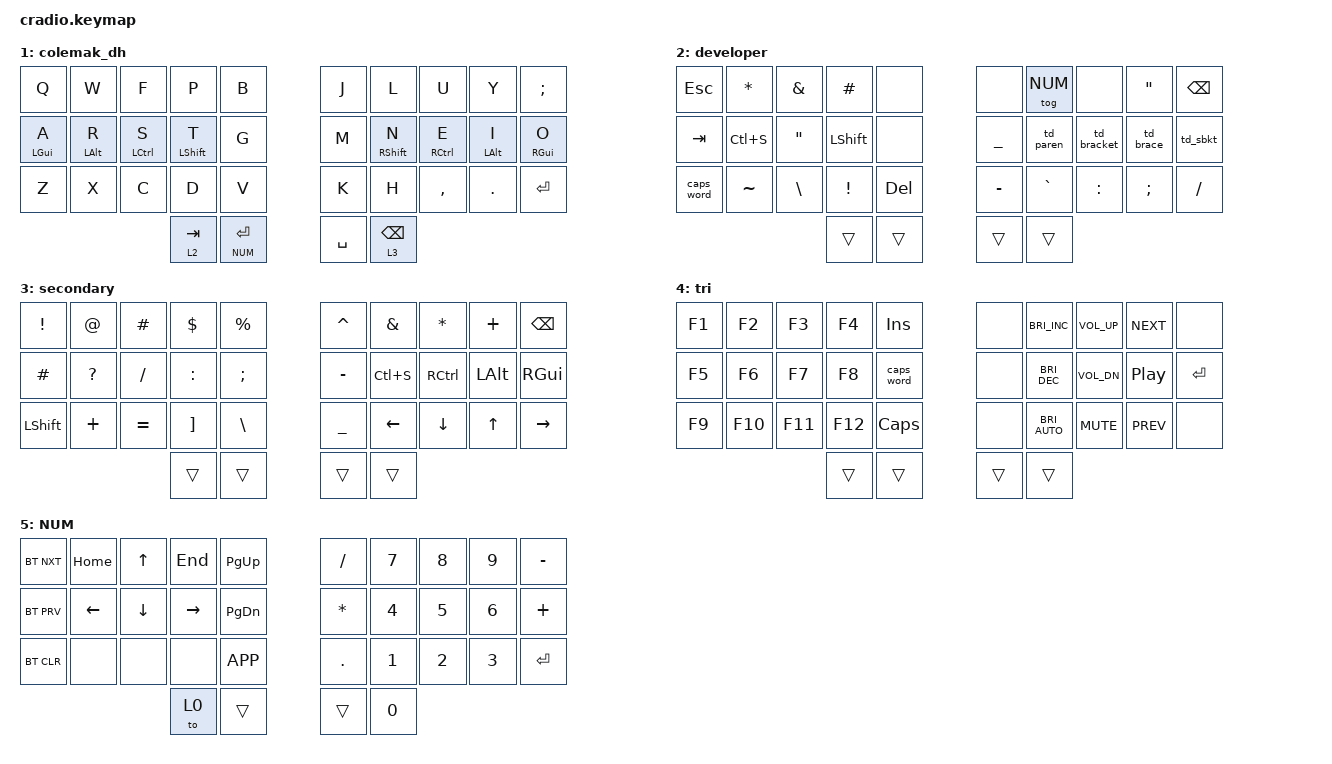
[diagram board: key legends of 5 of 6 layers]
/*
 * Copyright (c) 2020 The ZMK Contributors
 *
 * SPDX-License-Identifier: MIT
 */

#include <behaviors.dtsi>
#include <dt-bindings/zmk/keys.h>
#include <dt-bindings/zmk/bt.h>

#define QWERTY  0
#define COLEMAK 1
#define EDITOR  2
#define SECOND  3
#define TRI     4
#define NUM     5

// Home row mods macros
#define HRML(k1,k2,k3,k4) &ht LGUI k1  &ht LALT k2  &ht LCTRL k3  &ht LSHFT k4
#define HRMR(k1,k2,k3,k4) &ht RSHFT k1  &ht RCTRL k2  &ht LALT k3  &ht RGUI k4

&mt {
    tapping-term-ms = <500>;
};

/ {
    behaviors {
        td_paren: tap_dance_parenthesis {
            compatible = "zmk,behavior-tap-dance";
            label = "TAP_DANCE_PARENTHESIS";
            #binding-cells = <0>;
            tapping-term-ms = <200>;
            bindings = <&kp LEFT_PARENTHESIS>, <&kp RIGHT_PARENTHESIS>;
        };

        td_bracket: tap_dance_bracket {
            compatible = "zmk,behavior-tap-dance";
            label = "TAP_DANCE_BRACKET";
            #binding-cells = <0>;
            tapping-term-ms = <200>;
            bindings = <&kp LEFT_BRACKET>, <&kp RIGHT_BRACKET>;
        };

        td_brace: tap_dance_brace {
            compatible = "zmk,behavior-tap-dance";
            label = "TAP_DANCE_BRACE";
            #binding-cells = <0>;
            tapping-term-ms = <200>;
            bindings = <&kp LEFT_BRACE>, <&kp RIGHT_BRACE>;
        };

        td_sbkt: tap_dance_square_bracket {
            compatible = "zmk,behavior-tap-dance";
            label = "TAP_DANCE_SQUARE_BRACKET";
            #binding-cells = <0>;
            tapping-term-ms = <200>;
            bindings = <&kp LESS_THAN>, <&kp GREATER_THAN>;
        };

        hm: homerow_mods {
            compatible = "zmk,behavior-hold-tap";
            label = "HOMEROW_MODS";
            #binding-cells = <2>;
            flavor = "tap-preferred";
            tapping-term-ms = <200>;
            quick-tap-ms = <125>;
            global-quick-tap;
            bindings = <&kp>, <&kp>;
        };

        ht: hold_tap {
            label = "hold_tap";
            compatible = "zmk,behavior-hold-tap";
            #binding-cells = <2>;
            flavor = "tap-preferred";
            tapping-term-ms = <220>;
            quick-tap-ms = <150>;
            global-quick-tap;
            bindings = <&kp>, <&kp>;
        };
    };

    combos {
        compatible = "zmk,combos";
        
        combo_esc {
            timeout-ms = <50>;
            key-positions = <0 1>;
            bindings = <&kp ESC>;
        };
        
        combo_tab {
            timeout-ms = <50>;
            key-positions = <10 11>;
            bindings = <&kp TAB>;
        };
        
        combo_backspace {
            timeout-ms = <50>;
            key-positions = <8 9>;
            bindings = <&kp BACKSPACE>;
        };
        
        combo_qwerty {
            timeout-ms = <50>;
            key-positions = <30 33>;
            layers = <COLEMAK>;
            bindings = <&to QWERTY>;
        };
        
        combo_colemak {
            timeout-ms = <50>;
            key-positions = <30 33>;
            layers = <QWERTY>;
            bindings = <&to COLEMAK>;
        };
        
        layer_reset {
            timeout-ms = <50>;
            key-positions = <0 4 5 9>;
            bindings = <&to COLEMAK>;
        };
    };

    conditional_layers {
        compatible = "zmk,conditional-layers";
        tri_layer {
            if-layers = <EDITOR SECOND>;
            then-layer = <TRI>;
        };
    };

    keymap {
        // TODO: homerow mods on additional layers
        // TODO: mod to access control layer
        // TODO: windows, linux, iPadOs shortcut layers (enable layers and then use conditional layers for shortcut directing)
        // TODO: move SEMICOLON off of colemak/qwerty layers? maybe replace with ampersand?
        // TODO: modifiers to access F-keys and top-row symbols from numpad

        compatible = "zmk,keymap";
                
        qwerty {
            bindings = <
        //╭──────────┬──────────┬──────────┬──────────┬──────────╮   ╭──────────┬──────────┬──────────┬──────────┬──────────╮
        //│  Q       │  W       │  E       │  R       │  T       │   │  Y       │  U       │  I       │  O       │  P       │
            &kp Q      &kp W      &kp E      &kp R      &kp T          &kp Y      &kp U      &kp I      &kp O      &kp P
        //├──────────┼──────────┼──────────┼──────────┼──────────┤   ├──────────┼──────────┼──────────┼──────────┼──────────┤
        //│  A       │  S       │  D       │  F       │  G       │   │  H       │  J       │  K       │  L       │ ' "      │
            HRML(A,        S,         D,         F)     &kp G          &kp H      HRMR(J,        K,         L,        SQT)
        //├──────────┼──────────┼──────────┼──────────┼──────────┤   ├──────────┼──────────┼──────────┼──────────┼──────────┤
        //│  Z       │  X       │  C       │  V       │  B       │   │  N       │  M       │ , <      │ . >      │ / ?      │
            &kp Z      &kp X      &kp C      &kp V      &kp B          &kp N      &kp M      &kp COMMA  &kp DOT    &kp FSLH
        //╰──────────┴──────────┴──────────┼──────────┼──────────┤   ├──────────┼──────────┼──────────┴──────────┴──────────╯
                                            &lt 2 TAB  &lt 5 ENTER    &kp SPACE  &lt 3 BSPC
        //                                 ╰──────────┴──────────╯   ╰──────────┴──────────╯
            >;
        };
                
        colemak_dh {
            bindings = <
        //╭──────────┬──────────┬──────────┬──────────┬──────────╮   ╭──────────┬──────────┬──────────┬──────────┬──────────╮
        //│  Q       │  W       │  F       │  P       │  B       │   │  J       │  L       │  U       │  Y       │  ; :     │
           &kp Q      &kp W      &kp F      &kp P      &kp B          &kp J      &kp L      &kp U      &kp Y      &kp SEMICOLON
        //├──────────┼──────────┼──────────┼──────────┼──────────┤   ├──────────┼──────────┼──────────┼──────────┼──────────┤
        //│  A       │  R       │  S       │  T       │  G       │   │  M       │  N       │  E       │  I       │  O       │
           &hm LGUI A &hm LALT R &hm LCTRL S &hm LSHFT T &kp G        &kp M      &hm RSHFT N &hm RCTRL E &hm LALT I  &hm RGUI O
        //├──────────┼──────────┼──────────┼──────────┼──────────┤   ├──────────┼──────────┼──────────┼──────────┼──────────┤
        //│  Z       │  X       │  C       │  D       │  V       │   │  K       │  H       │  , <     │  . >     │ enter     
           &kp Z      &kp X      &kp C      &kp D      &kp V          &kp K      &kp H      &kp COMMA  &kp DOT    &kp RETURN
        //╰──────────┴──────────┴──────────┼──────────┼──────────┤   ├──────────┼──────────┼──────────┴──────────┴──────────╯
                                            &lt 2 TAB  &lt NUM ENTER  &kp SPACE  &lt 3 BSPC
        //                                 ╰──────────┴──────────╯   ╰──────────┴──────────╯
            >;
        };

        developer {
            bindings = <
                &kp ESC     &kp STAR    &kp AMPS    &kp HASH    &none           &none       &tog NUM &none       &kp DQT     &kp BACKSPACE
                &kp TAB     &kp LC(S)   &kp DQT     &kp LSHFT   &none           &kp UNDER   &td_paren   &td_bracket &td_brace   &td_sbkt
                &caps_word  &kp TILDE   &kp BSLH    &kp EXCL    &kp DEL         &kp MINUS   &kp GRAVE   &kp COLON   &kp SEMI    &kp SLASH
                                                    &trans      &trans          &trans      &trans
            >;
        };
        
        secondary {
            bindings = <
                &kp EXCL    &kp AT      &kp HASH    &kp DLLR    &kp PRCNT       &kp CARET   &kp AMPS    &kp STAR    &kp PLUS    &kp BACKSPACE
                &kp HASH    &kp QMARK   &kp FSLH    &kp COLON   &kp SEMI        &kp MINUS   &kp LC(S)   &kp RCTRL   &kp LALT    &kp RGUI
                &kp LSHFT   &kp PLUS    &kp EQUAL   &kp RBKT    &kp BSLH        &kp UNDER   &kp LEFT    &kp DOWN    &kp UP      &kp RIGHT
                                                    &trans      &trans          &trans      &trans
            >;
        };    
        
        tri {
            bindings = <
                &kp F1      &kp F2      &kp F3      &kp F4      &kp INS         &none       &kp C_BRI_INC   &kp K_VOL_UP    &kp C_NEXT       &none
                &kp F5      &kp F6      &kp F7      &kp F8      &caps_word      &none       &kp C_BRI_DEC   &kp K_VOL_DN    &kp C_PLAY_PAUSE &kp ENTER
                &kp F9      &kp F10     &kp F11     &kp F12     &kp CAPSLOCK    &none       &kp C_BRI_AUTO  &kp K_MUTE      &kp C_PREV       &none
                                                    &trans      &trans          &trans      &trans 
            >;
        };
        
        NUM {
            bindings = <
                &bt BT_NXT  &kp HOME    &kp UP      &kp END     &kp PG_UP       &kp SLASH   &kp N7          &kp N8          &kp N9      &kp MINUS
                &bt BT_PRV  &kp LEFT    &kp DOWN    &kp RIGHT   &kp PG_DN       &kp STAR    &kp N4          &kp N5          &kp N6      &kp PLUS
                &bt BT_CLR  &none       &none       &none       &kp K_APP       &kp DOT     &kp N1          &kp N2          &kp N3      &kp RET
                                                    &to 0       &trans          &trans      &kp N0
            >;
        };
    };

    chosen {
      zmk,battery = &vbatt;
    };

    vbatt: vbatt {
        compatible = "zmk,battery-nrf-vddh";
        label = "VBATT";
    };
};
